VERSION "HIPBNYYYYYYYYYYYYYYYYYYYYYYYYYYYYYYYYYYYYY/4/%%%/4/'%**4YYY///"

NS_ :

BS_:

BU_:

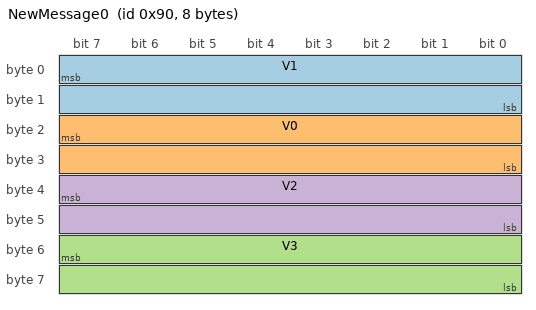
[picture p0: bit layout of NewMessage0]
BO_ 144 NewMessage0: 8 Vector__XXX
 SG_ V1 : 7|16@0+ (1,0) [0|0] "" Vector__XXX
 SG_ V0 : 23|16@0+ (1,0) [0|0] "" Vector__XXX
 SG_ V3 : 55|16@0+ (1,0) [0|0] "" Vector__XXX
 SG_ V2 : 39|16@0+ (1,0) [0|0] "" Vector__XXX
